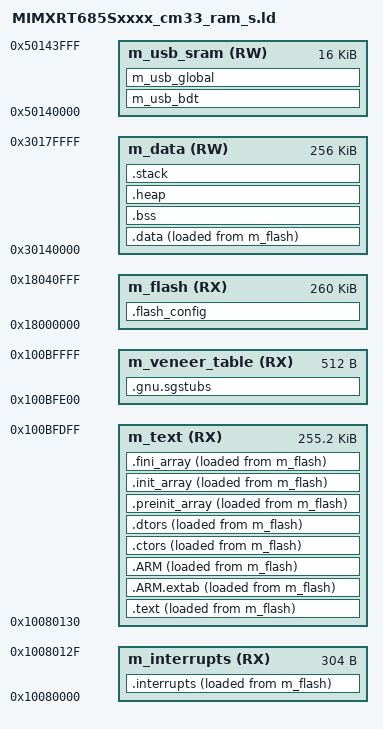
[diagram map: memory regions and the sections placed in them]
/*
** ###################################################################
**     Processors:          MIMXRT685SFAWBR_cm33
**                          MIMXRT685SFFOB_cm33
**                          MIMXRT685SFVKB_cm33
**
**     Compiler:            GNU C Compiler
**     Reference manual:    MIMXRT685 User manual Rev. 0.95 11 November 2019
**     Version:             rev. 1.0, 2018-06-19
**     Build:               b201029
**
**     Abstract:
**         Linker file for the GNU C Compiler
**
**     Copyright 2016 Freescale Semiconductor, Inc.
**     Copyright 2016-2020 NXP
**     All rights reserved.
**
**     SPDX-License-Identifier: BSD-3-Clause
**
**     http:                 www.nxp.com
**     mail:                 support@nxp.com
**
** ###################################################################
*/



/* Entry Point */
ENTRY(Reset_Handler)

HEAP_SIZE  = DEFINED(__heap_size__)  ? __heap_size__  : 0x0400;
STACK_SIZE = DEFINED(__stack_size__) ? __stack_size__ : 0x0400;

/* Specify the memory areas */
/* The SRAM region [0x10000-0x1BFFF] is reserved for ROM code. */
/* The SRAM region [0x0-0xFFFF], [0x1C000-0x1FFFF] is reserved for app-specific use cases. */
/* The SRAM region [0x20000-0x7FFFF] is reserved for Non-cached shared memory between M33 and DSP. */
MEMORY
{
  m_flash               (RX)  : ORIGIN = 0x18000000, LENGTH = 0x00041000
  m_interrupts          (RX)  : ORIGIN = 0x10080000, LENGTH = 0x00000130
  m_text                (RX)  : ORIGIN = 0x10080130, LENGTH = 0x0003FCD0
  m_veneer_table        (RX)  : ORIGIN = 0x100BFE00, LENGTH = 0x00000200
  m_data                (RW)  : ORIGIN = 0x30140000, LENGTH = 0x00040000
  m_usb_sram            (RW)  : ORIGIN = 0x50140000, LENGTH = 0x00004000
}

/* Define output sections */
SECTIONS
{
  .flash_config :
  {
    FILL(0x00)
    __FLASH_BASE = .;
    . = 0x400 ;
    KEEP(* (.flash_conf))     /* flash config section */
    . = 0x1000 ;
  } > m_flash

  /* The startup code goes first into internal ram */
  .interrupts :
  {
    . = ALIGN(4);
    __VECTOR_TABLE = .;
    __Vectors = .;
    KEEP(*(.isr_vector))     /* Startup code */
    . = ALIGN(4);
  } > m_interrupts AT> m_flash

  /* The program code and other data goes into internal ram */
  .text :
  {
    . = ALIGN(4);
    *(.text)                 /* .text sections (code) */
    *(.text*)                /* .text* sections (code) */
    *(.rodata)               /* .rodata sections (constants, strings, etc.) */
    *(.rodata*)              /* .rodata* sections (constants, strings, etc.) */
    *(.glue_7)               /* glue arm to thumb code */
    *(.glue_7t)              /* glue thumb to arm code */
    *(.eh_frame)
    KEEP (*(.init))
    KEEP (*(.fini))
    . = ALIGN(4);
  } > m_text AT> m_flash


  .ARM.extab :
  {
    *(.ARM.extab* .gnu.linkonce.armextab.*)
  } > m_text AT> m_flash

  .ARM :
  {
    __exidx_start = .;
    *(.ARM.exidx*)
    __exidx_end = .;
  } > m_text AT> m_flash

 .ctors :
  {
    __CTOR_LIST__ = .;
    /* gcc uses crtbegin.o to find the start of
       the constructors, so we make sure it is
       first.  Because this is a wildcard, it
       doesn't matter if the user does not
       actually link against crtbegin.o; the
       linker won't look for a file to match a
       wildcard.  The wildcard also means that it
       doesn't matter which directory crtbegin.o
       is in.  */
    KEEP (*crtbegin.o(.ctors))
    KEEP (*crtbegin?.o(.ctors))
    /* We don't want to include the .ctor section from
       from the crtend.o file until after the sorted ctors.
       The .ctor section from the crtend file contains the
       end of ctors marker and it must be last */
    KEEP (*(EXCLUDE_FILE(*crtend?.o *crtend.o) .ctors))
    KEEP (*(SORT(.ctors.*)))
    KEEP (*(.ctors))
    __CTOR_END__ = .;
  } > m_text AT> m_flash

  .dtors :
  {
    __DTOR_LIST__ = .;
    KEEP (*crtbegin.o(.dtors))
    KEEP (*crtbegin?.o(.dtors))
    KEEP (*(EXCLUDE_FILE(*crtend?.o *crtend.o) .dtors))
    KEEP (*(SORT(.dtors.*)))
    KEEP (*(.dtors))
    __DTOR_END__ = .;
  } > m_text AT> m_flash

  .preinit_array :
  {
    PROVIDE_HIDDEN (__preinit_array_start = .);
    KEEP (*(.preinit_array*))
    PROVIDE_HIDDEN (__preinit_array_end = .);
  } > m_text AT> m_flash

  .init_array :
  {
    PROVIDE_HIDDEN (__init_array_start = .);
    KEEP (*(SORT(.init_array.*)))
    KEEP (*(.init_array*))
    PROVIDE_HIDDEN (__init_array_end = .);
  } > m_text AT> m_flash

  .fini_array :
  {
    PROVIDE_HIDDEN (__fini_array_start = .);
    KEEP (*(SORT(.fini_array.*)))
    KEEP (*(.fini_array*))
    PROVIDE_HIDDEN (__fini_array_end = .);
  } > m_text AT> m_flash

  __etext = .;    /* define a global symbol at end of code */
  __DATA_ROM = .; /* Symbol is used by startup for data initialization */

  __VECTOR_RAM = ORIGIN(m_interrupts);
  __RAM_VECTOR_TABLE_SIZE_BYTES = 0x0;

  .data :
  {
    . = ALIGN(4);
    __DATA_RAM = .;
    __data_start__ = .;      /* create a global symbol at data start */
    *(CodeQuickAccess)       /* CodeQuickAccess sections */
    *(DataQuickAccess)       /* DataQuickAccess sections */
    *(.data)                 /* .data sections */
    *(.data*)                /* .data* sections */
    KEEP(*(.jcr*))
    . = ALIGN(4);
    __data_end__ = .;        /* define a global symbol at data end */
  } > m_data AT> m_flash

  /* section for veneer table */
  .gnu.sgstubs : AT(ORIGIN(m_flash) + 0x1000 + ORIGIN(m_veneer_table) - ORIGIN(m_interrupts))
  {
     . = ALIGN(32);
     _start_sg = .;
    *(.gnu.sgstubs*)
     . = ALIGN(32);
     _end_sg = .;
  } > m_veneer_table

  __DATA_END = __DATA_ROM + (__data_end__ - __data_start__);
  _image_size = __DATA_END - __VECTOR_TABLE;
  ASSERT(_image_size <= LENGTH(m_flash), "region m_flash overflowed with text and data")

  /* Uninitialized data section */
  .bss :
  {
    /* This is used by the startup in order to initialize the .bss section */
    . = ALIGN(4);
    __START_BSS = .;
    __bss_start__ = .;
    *(.bss)
    *(.bss*)
    *(COMMON)
    . = ALIGN(4);
    __bss_end__ = .;
    __END_BSS = .;
  } > m_data

  .heap :
  {
    . = ALIGN(8);
    __end__ = .;
    PROVIDE(end = .);
    __HeapBase = .;
    . += HEAP_SIZE;
    __HeapLimit = .;
    __heap_limit = .; /* Add for _sbrk */
  } > m_data

  .stack :
  {
    . = ALIGN(8);
    . += STACK_SIZE;
  } > m_data

  m_usb_bdt (NOLOAD) :
  {
    . = ALIGN(512);
    *(m_usb_bdt)
  } > m_usb_sram

  m_usb_global (NOLOAD) :
  {
    *(m_usb_global)
  } > m_usb_sram

  /* Initializes stack on the end of block */
  __StackTop   = ORIGIN(m_data) + LENGTH(m_data);
  __StackLimit = __StackTop - STACK_SIZE;
  PROVIDE(__stack = __StackTop);

  .ARM.attributes 0 : { *(.ARM.attributes) }

  ASSERT(__StackLimit >= __HeapLimit, "region m_data overflowed with stack and heap")
}

